# STM32U575 register map
File version: 1.3
CPU: CM33 r0p1, little endian, MPU, FPU, 4 interrupt priority bits
Registers are 32-bit, read-write, reset 0x0 unless marked. A register's access mark holds for its fields unless they carry their own. Offsets are from the block's base; [hi:lo] are bit positions; {n}, {i} and the like mark numbered series.

## DLYBOS1 — The delay block (DLYB) is used to generate an output clock that is dephased from the input clock
Base 0x420CF000
Same registers: DLYBSD1 0x420C8400, DLYBSD2 0x420C8800, DLYBOS2 0x420CF400, SEC_DLYBSD1 0x520C8400, SEC_DLYBSD2 0x520C8800, SEC_DLYBOS1 0x520CF000, SEC_DLYBOS2 0x520CF400
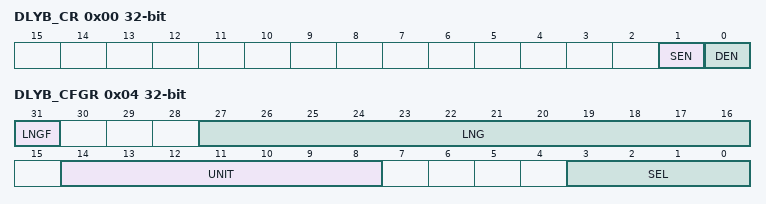
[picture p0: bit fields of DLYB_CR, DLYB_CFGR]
0x00 DLYB_CR — control register
  [1] SEN — OPALPM
  [0] DEN — Operational amplifier Enable
0x04 DLYB_CFGR access per field — configuration register
  [31] LNGF ro, [27:16] LNG ro, [14:8] UNIT rw, [3:0] SEL rw

## SAES — Secure AES coprocessor
Base 0x420C0C00
Same registers: SEC_SAES 0x520C0C00
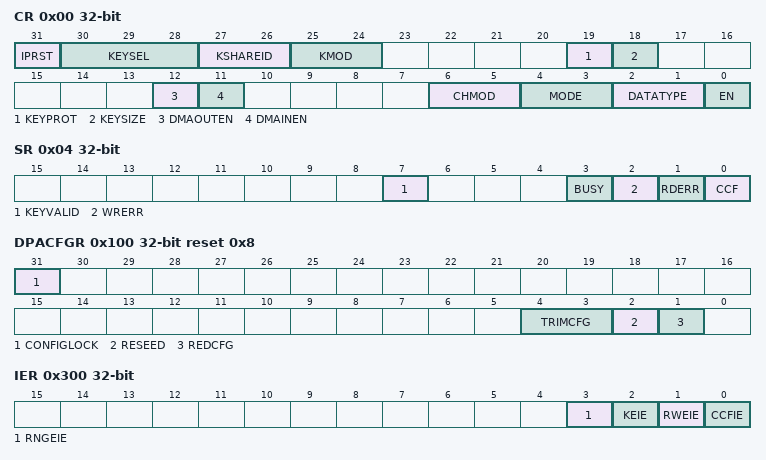
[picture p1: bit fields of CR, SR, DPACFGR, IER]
0x00 CR — control register
  [31] IPRST
  [30:28] KEYSEL
  [27:26] KSHAREID
  [25:24] KMOD
  [19] KEYPROT
  [18] KEYSIZE
  [12] DMAOUTEN
  [11] DMAINEN
  [6:5] CHMOD
  [4:3] MODE
  [2:1] DATATYPE
  [0] EN — SAES enable
0x04 SR ro — status register
  [7] KEYVALID — Key Valid flag
  [3] BUSY
  [2] WRERR — Write error flag
  [1] RDERR — Read error flag
  [0] CCF — Computation complete flag
0x08 DINR wo — data input register
  [31:0] DIN — Input data word
0x0C DOUTR ro — data output register
  [31:0] DOUT — Output data word
0x10 KEYR0 wo — key register 0
  [31:0] KEY — Cryptographic key, bits [31:0]
0x14 KEYR1 wo — key register 1
  [31:0] KEY — Cryptographic key, bits [63:32]
0x18 KEYR2 wo — key register 2
  [31:0] KEYR — Cryptographic key, bits [95:64]
0x1C KEYR3 wo — key register 3
  [31:0] SAES_KEYR3 — Cryptographic key, bits [127:96]
{0x20+4i} IVR{i} (i=0..3) — initialization vector register {i}
  [31:0] IVI — Initialization vector input, bits [{32i+31}:{32i}]
{0x20+4i} KEYR{i} wo (i=4..7) — key register {i}
  [31:0] KEY — Cryptographic key, bits [{32i+31}:{32i}]
0x100 DPACFGR access per field reset 0x8 — configuration register
  [31] CONFIGLOCK ro, [4:3] TRIMCFG rw, [2] RESEED rw, [1] REDCFG rw
0x300 IER — interrupt enable register
  [3] RNGEIE
  [2] KEIE — Key error interrupt enable
  [1] RWEIE — Read or write error interrupt enable
  [0] CCFIE — Computation complete flag interrupt enable
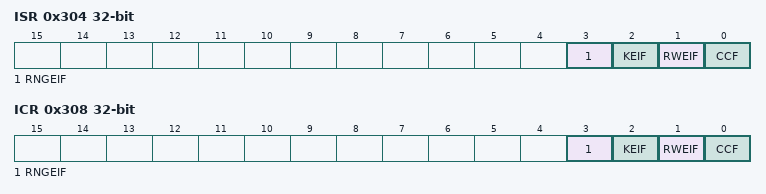
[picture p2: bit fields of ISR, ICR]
0x304 ISR ro — interrupt status register
  [3] RNGEIF
  [2] KEIF — Key error interrupt flag
  [1] RWEIF — Read or write error interrupt flag
  [0] CCF — Computation complete flag
0x308 ICR wo — interrupt clear register
  [3] RNGEIF
  [2] KEIF — Key error interrupt flag clear
  [1] RWEIF — Read or write error interrupt flag clear
  [0] CCF — Computation complete flag clear

## PSSI
Base 0x4202C400
Same registers: SEC_PSSI 0x5202C400
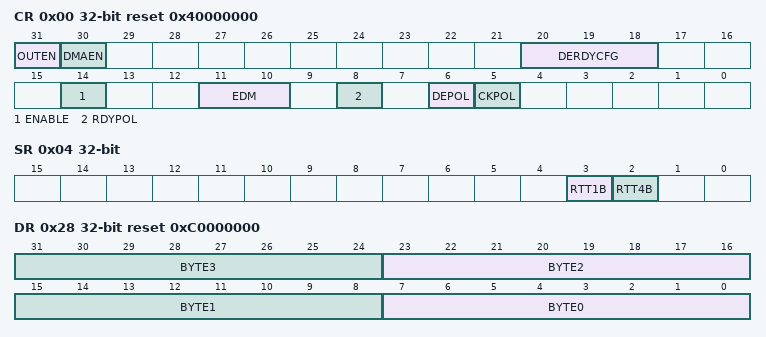
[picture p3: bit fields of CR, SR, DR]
0x00 CR reset 0x40000000 — PSSI control register
  [31] OUTEN — Data direction selection bit
  [30] DMAEN — DMA enable bit
  [20:18] DERDYCFG — Data enable and ready configuration When the PSSI_RDY function is mapped to the PSSI_DE pin (settings 101 or 111), it is still the RDYPOL bit which determines its polarity. Similarly, when the PSSI_DE function is mapped to the PSSI_RDY pin (settings 110 or 111), it is still the DEPOL bit which determines its polarity.
  [14] ENABLE — PSSI enable The contents of the FIFO are flushed when ENABLE is cleared to 0. Note: When ENABLE=1, the content of PSSI_CR must not be changed, except for the ENABLE bit itself. All configuration bits can change as soon as ENABLE changes from 0 to 1. The DMA controller and all PSSI configuration registers must be programmed correctly before setting the ENABLE bit to 1. The ENABLE bit and the DCMI ENABLE bit (bit 15 of DCMI_CR) must not be set to 1 at the same time.
  [11:10] EDM — Extended data mode
  [8] RDYPOL — Ready (PSSI_RDY) polarity This bit indicates the level on the PSSI_RDY pin when the data are not valid on the parallel interface.
  [6] DEPOL — Data enable (PSSI_DE) polarity This bit indicates the level on the PSSI_DE pin when the data are not valid on the parallel interface.
  [5] CKPOL — Parallel data clock polarity This bit configures the capture edge of the parallel clock or the edge used for driving outputs, depending on OUTEN.
0x04 SR ro — PSSI status register
  [3] RTT1B, [2] RTT4B
0x08 RIS ro — PSSI raw interrupt status register
  [1] OVR_RIS
0x0C IER — PSSI interrupt enable register
  [1] OVR_IE
0x10 MIS ro — PSSI masked interrupt status register
  [1] OVR_MIS
0x14 ICR wo — PSSI interrupt clear register
  [1] OVR_ISC
0x28 DR reset 0xC0000000 — PSSI data register
  [8n+7:8n] BYTE{n} (n=0..3) — Data byte {n}
